# CH32V30X register map
Vendor: WCH Ltd.; File version: 1.0
Registers are 32-bit, read-write, reset 0x0 unless marked. A register's access mark holds for its fields unless they carry their own. Offsets are from the block's base; [hi:lo] are bit positions; {n}, {i} and the like mark numbered series.

## USART1 — Universal synchronous asynchronous receiver transmitter
Base 0x40013800
Same registers: UART6 0x40001800, UART7 0x40001C00, UART8 0x40002000, USART2 0x40004400, USART3 0x40004800, UART4 0x40004C00, UART5 0x40005000
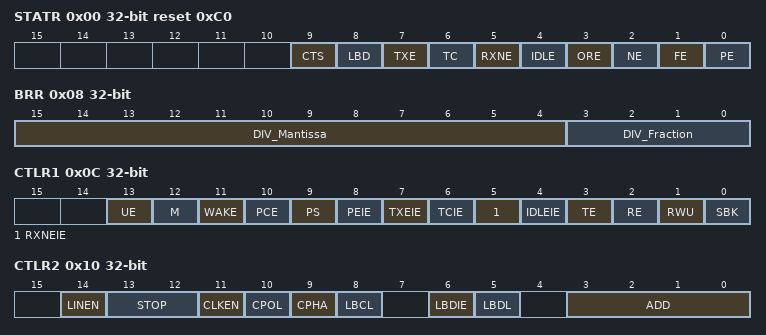
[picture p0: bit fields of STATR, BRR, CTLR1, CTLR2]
0x00 STATR access per field reset 0xC0 — Status register
  [9] CTS rw — CTS flag
  [8] LBD rw — LIN break detection flag
  [7] TXE ro — Transmit data register empty
  [6] TC rw — Transmission complete
  [5] RXNE rw — Read data register not empty
  [4] IDLE ro — IDLE line detected
  [3] ORE ro — Overrun error
  [2] NE ro — Noise error flag
  [1] FE ro — Framing error
  [0] PE ro — Parity error
0x04 DATAR — Data register
  [8:0] DR — Data value
0x08 BRR — Baud rate register
  [15:4] DIV_Mantissa — mantissa of USARTDIV
  [3:0] DIV_Fraction — fraction of USARTDIV
0x0C CTLR1 — Control register 1
  [13] UE — USART enable
  [12] M — Word length
  [11] WAKE — Wakeup method
  [10] PCE — Parity control enable
  [9] PS — Parity selection
  [8] PEIE — PE interrupt enable
  [7] TXEIE — TXE interrupt enable
  [6] TCIE — Transmission complete interrupt enable
  [5] RXNEIE — RXNE interrupt enable
  [4] IDLEIE — IDLE interrupt enable
  [3] TE — Transmitter enable
  [2] RE — Receiver enable
  [1] RWU — Receiver wakeup
  [0] SBK — Send break
0x10 CTLR2 — Control register 2
  [14] LINEN — LIN mode enable
  [13:12] STOP — STOP bits
  [11] CLKEN — Clock enable
  [10] CPOL — Clock polarity
  [9] CPHA — Clock phase
  [8] LBCL — Last bit clock pulse
  [6] LBDIE — LIN break detection interrupt enable
  [5] LBDL — lin break detection length
  [3:0] ADD — Address of the USART node
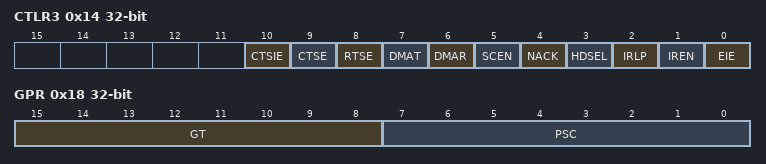
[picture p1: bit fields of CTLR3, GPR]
0x14 CTLR3 — Control register 3
  [10] CTSIE — CTS interrupt enable
  [9] CTSE — CTS enable
  [8] RTSE — RTS enable
  [7] DMAT — DMA enable transmitter
  [6] DMAR — DMA enable receiver
  [5] SCEN — Smartcard mode enable
  [4] NACK — Smartcard NACK enable
  [3] HDSEL — Half-duplex selection
  [2] IRLP — IrDA low-power
  [1] IREN — IrDA mode enable
  [0] EIE — Error interrupt enable
0x18 GPR — Guard time and prescaler register
  [15:8] GT — Guard time value
  [7:0] PSC — Prescaler value

## DBG — Debug support
Base 0xE000D000
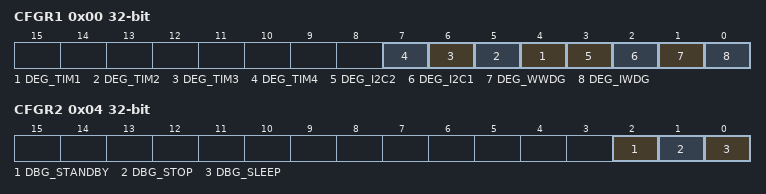
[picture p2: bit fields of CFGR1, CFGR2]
0x00 CFGR1 — DBGMCU_CFGR1
  [n+3] DEG_TIM{n} (n=1..4), [3] DEG_I2C2, [2] DEG_I2C1, [1] DEG_WWDG, [0] DEG_IWDG
0x04 CFGR2 — DBGMCU_CFGR2
  [2] DBG_STANDBY, [1] DBG_STOP, [0] DBG_SLEEP

## CRC — CRC calculation unit
Base 0x40023000
0x00 DATAR reset 0xFFFFFFFF — Data register
  [31:0] DR — Data Register
0x04 IDATAR — Independent Data register
  [7:0] IDR
0x08 CTLR wo — Control register
  [0] RESET — Reset bit

## FLASH
Base 0x40022000
0x04 KEYR wo — Flash key register
  [31:0] KEYR — FPEC key
0x08 OBKEYR wo — Flash option key register
  [31:0] OPTKEY — Option byte key
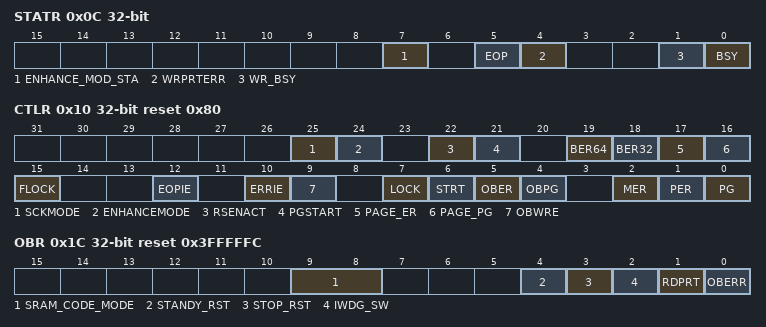
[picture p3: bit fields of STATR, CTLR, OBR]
0x0C STATR access per field — Status register
  [7] ENHANCE_MOD_STA ro — Enhance mode start
  [5] EOP rw — End of operation
  [4] WRPRTERR rw — Write protection error
  [1] WR_BSY ro — Quick page programming
  [0] BSY ro — Busy
0x10 CTLR reset 0x80 — Control register
  [25] SCKMODE — Flash SCK mode
  [24] ENHANCEMODE — Flash Enhance read mode
  [22] RSENACT — Reset Flash Enhance read mode
  [21] PGSTART — Page Programming Start
  [19] BER64 — Block Erase 64K
  [18] BER32 — Block Erase 32K
  [17] PAGE_ER — Fast erase
  [16] PAGE_PG — Fast programming
  [15] FLOCK — Fast programmable lock
  [12] EOPIE — End of operation interrupt enable
  [10] ERRIE — Error interrupt enable
  [9] OBWRE — Option bytes write enable
  [7] LOCK
  [6] STRT — Start
  [5] OBER — Option byte erase
  [4] OBPG — Option byte programming
  [2] MER — Mass Erase
  [1] PER — Page Erase
  [0] PG — Programming
0x14 ADDR wo — Flash address register
  [31:0] FAR — Flash Address
0x1C OBR ro reset 0x3FFFFFC — Option byte register
  [9:8] SRAM_CODE_MODE
  [4] STANDY_RST
  [3] STOP_RST
  [2] IWDG_SW
  [1] RDPRT — Read protection
  [0] OBERR — Option byte error
0x20 WPR ro reset 0xFFFFFFFF — Write protection register
  [31:0] WRP — Write protect
0x24 MODEKEYR wo — Mode select register
  [31:0] MODEKEYR — Mode select
